AUTOSAR XML (schema 4-2-1)
package /ComponentTypes
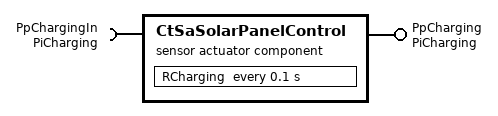
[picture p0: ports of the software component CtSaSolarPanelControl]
  sensor actuator sw component type CtSaSolarPanelControl
    provide port PpCharging: nonqueued-sender-com-spec{data-element=DeCharging, init-value=constant-reference=CCharging}, provided-interface=PiCharging
    require port PpChargingIn: nonqueued-receiver-com-spec{data-element=DeCharging, filter=data-filter-type=ALWAYS, init-value=constant-reference=CCharging}, required-interface=PiCharging
    behavior CtSaSolarPanelControl_InternalBehavior: data-type-mapping=ApMappingSet
      timing event TMT_RCharging: start-on-event=RCharging, period=0.1
      runnable RCharging
        data-receive-point-by-arguments:
          access REC_PpChargingIn_DeCharging: accessed-variable=PpChargingIn.DeCharging
        data-send-points:
          access SEND_PpCharging_DeCharging: accessed-variable=PpCharging.DeCharging
  swc implementation CtSaSolarPanelControl_Implementation: behavior=CtSaSolarPanelControl_InternalBehavior
    code-descriptors:
      code Default: artifact-descriptors=autosar-engineering-object={short-label=Default, category=SWSRC}
